# nrf9120_modem register map
Vendor: Nordic Semiconductor; Series: nrf91; File version: 1
CPU: CM4 r0p1, little endian, MPU, FPU, 3 interrupt priority bits
Registers are 32-bit, read-write, reset 0x0 unless marked. A register's access mark holds for its fields unless they carry their own. Offsets are from the block's base; [hi:lo] are bit positions; lines under a group give offsets from that group; 'fields as' and 'values as' point back to an identical list.

## MCPLL_NS — Modem Clock PLL
Base 0x40010000
0x00 TASKS_START wo — Start MCPLL
  [0] TASKS_START
    1=Trigger task
0x04 TASKS_UPDATE wo — Update CONTROL.FRAC and CONTROL.INT values
  [0] TASKS_UPDATE
    1=Trigger task
0x08 TASKS_STOP wo — Stop MCPLL
  [0] TASKS_STOP
    1=Trigger task
0x100 EVENTS_LOCKERROR — Error event, MCPLL no longer in lock
  [0] EVENTS_LOCKERROR
    0=NotGenerated (Event not generated); 1=Generated (Event generated)
0x300 INTEN — Enable or disable interrupt
  [0] LOCKERROR — Enable or disable interrupt for event LOCKERROR
    0=Disabled; 1=Enabled
0x304 INTENSET — Enable interrupt
  [0] LOCKERROR — Write '1' to enable interrupt for event LOCKERROR
    on read: 0=Disabled (Read: Disabled); 1=Enabled (Read: Enabled) | on write: 1=Set (Enable)
0x308 INTENCLR — Disable interrupt
  [0] LOCKERROR — Write '1' to disable interrupt for event LOCKERROR
    on read: 0=Disabled (Read: Disabled); 1=Enabled (Read: Enabled) | on write: 1=Clear (Disable)
0x30C INTPEND ro — Pending interrupts
  [0] LOCKERROR — Read pending status of interrupt for event LOCKERROR
    on read: 0=NotPending (Read: Not pending); 1=Pending (Read: Pending)
0x400 INLOCK ro — MCPLL locked or not
  [0] INLOCK
    0=NotInLock (MCPLL not locked); 1=InLock (MCPLL locked)
0x504 CONTROL group — Unspecified
  0x00 INT reset 0x12 — Integer part of the control word.
    [5:0] INT — Integer part of the control word
  0x04 FRAC — Fractional part of the control word.
    [22:0] FRAC — Fractional part of the control word
0x510 MA reset 0x3 — Post division ratio for OUTA
  [2:0] MA
    0=BYPASS; 1=CLK614M4 (614.4 MHz); 2=CLK307M2 (307.2 MHz); 3=CLK153M6 (153.6 MHz); 4=CLK76M8 (76.8 MHz); 5=CLK163M84 (163.84 MHz); 6=REFIN (32 MHz); 7=GND (Nothing)
0x514 MB reset 0x4 — Post division ratio for OUTB
  [2:0] MB
    0=BYPASS; 1=CLK614M4 (614.4 MHz); 2=CLK307M2 (307.2 MHz); 3=CLK153M6 (153.6 MHz); 4=CLK76M8 (76.8 MHz); 5=CLK38M4 (38.4 MHz); 6=REFIN (32 MHz); 7=GND (Nothing)
0x518 MC reset 0x3 — Post division ratio for OUTC
  [2:0] MC
    values as MA.MA
0x51C MD reset 0x7 — Post division ratio for OUTD
  [2:0] MD
    values as MB.MB
0x520 FORCEINLOCK — Force MCPLL in lock
  [1:0] FORCEINLOCK — Force MCPLL in lock (value)
0x524 RESET — Reset MCPLL
  [0] RESET — Software reset (ARSTSD)
0x528 SPARE — Spare signals
  [3:0] SPARE
0x530 OVERRIDE group — Override mechanism
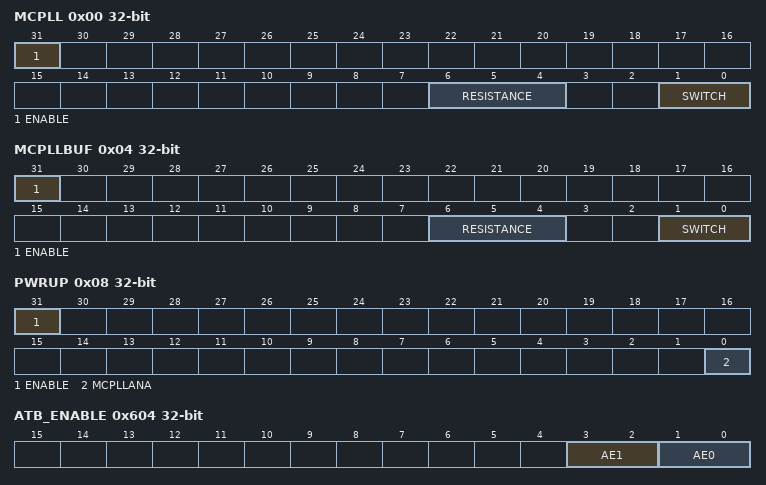
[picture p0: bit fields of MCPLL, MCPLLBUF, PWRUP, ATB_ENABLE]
  0x00 MCPLL — Override for MCPLL power switch
    [31] ENABLE — Enable override
      0=No override enabled; 1=Override enabled
    [6:4] RESISTANCE — Power switch resistance override value
    [1:0] SWITCH — Power switch override value
      0=OFF (Force power switch OFF); 1=ON (Force power switch ON)
  0x04 MCPLLBUF — Override for MCPLLBUF power switch
    fields as OVERRIDE.MCPLL
  0x08 PWRUP — Override for power up
    [31] ENABLE — Enable override
      0=No override enabled; 1=Override enabled
    [0] MCPLLANA — Override for PWRDUP_MCPLL
      0=OFF (Force power off); 1=ON (Force power on)
0x540 OUTA_DRV reset 0x1 — Drive strength for OUTA
  [1:0] OUTA_DRV
0x544 OUTB_DRV reset 0x1 — Drive strength for OUTB
  [1:0] OUTB_DRV
0x548 OUTC_DRV reset 0x1 — Drive strength for OUTC
  [1:0] OUTC_DRV
0x54C OUTD_DRV reset 0x1 — Drive strength for OUTD
  [1:0] OUTD_DRV
0x550 INTMODE — Integer mode
  [0] INTMODE
    0=Fractional mode; 1=Integer mode
0x600 TEST — ATE test bus control
  [3:0] ATE
0x604 ATB_ENABLE — Analog switch control for connecting ATB to GPIOs. Note that when the analog switch is enabled, digital driver of the GPIO must be in hiZ. Note also that the analog switch can be enabled also from elsewhere for testing other analog IPs.
  [3:2] AE1
    0=Disconnected (No analog test signal connected (Alta: GPIO29).); 1=ATB1 (ATB1 connected. This controls only the GPIO analog switch. In order to get the test signal to GPIO.); 2=BYPASSCLK (MCPLL input connected. Can be used as reference or bypass clock.); 3=NOTALLOWED (Not allowed (both slices enabled).)
  [1:0] AE0
    0=Disconnected (No analog test signal connected (Alta: GPIO28).); 1=ATB0 (ATB0 connected. This controls only the GPIO analog switch. In order to get the test signal to GPIO.); 2=OUTD (MCPLL OUTD output connected.); 3=NOTALLOWED (Not allowed (both slices enabled).)
